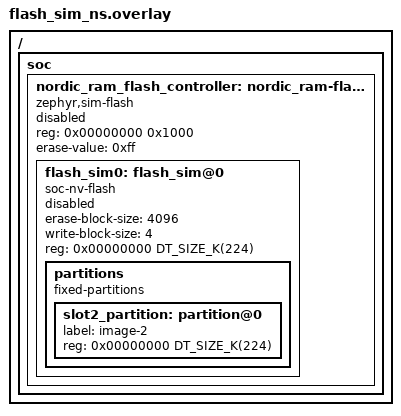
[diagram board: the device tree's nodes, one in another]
/*
 * Copyright (c) 2024 Nordic Semiconductor ASA
 *
 * SPDX-License-Identifier: LicenseRef-Nordic-5-Clause
 */

#include <mem.h>

/*
 * Variant of flash_sim.overlay for TF-M (non-secure) default images.
 *
 * flash_sim.overlay sets `chosen zephyr,sram = &sram0_offset_for_dfu;` which
 * places the application's RAM at absolute 0x20002000 - well inside sram0_s
 * (the secure SRAM region reserved for TF-M). The NS app would then end up
 * with its initial MSP inside secure memory and fault with SFSR.AUVIOL on
 * the very first exception push. For non-secure board targets we keep the
 * board's default zephyr,sram (sram0_ns_app) but still expose the simulated
 * flash controller + slot2_partition so that the nrf DFU zip packager can
 * resolve the slot2_partition node label.
 */

/ {
	soc {
		nordic_ram_flash_controller: nordic_ram-flash-controller@0 {
			compatible = "zephyr,sim-flash";
			reg = <0x00000000 0x1000>;
			#address-cells = <1>;
			#size-cells = <1>;
			erase-value = <0xff>;
			status = "disabled";

			/* This node label must match that used in the flash simulator. */
			flash_sim0: flash_sim@0 {
				status = "disabled";
				compatible = "soc-nv-flash";
				erase-block-size = <4096>;
				write-block-size = <4>;
				reg = <0x00000000 DT_SIZE_K(224)>;

				partitions {
					compatible = "fixed-partitions";
					#address-cells = <1>;
					#size-cells = <1>;

					slot2_partition: partition@0 {
						label = "image-2";
						reg = <0x00000000 DT_SIZE_K(224)>;
					};
				};
			};
		};
	};
};
